[part 1 of 3: packages /MICROSAR/Dem_swc/DataTypes to /MICROSAR/Dem_swc/ComponentTypes]
AUTOSAR XML (schema 4-3-0)
package /MICROSAR/Dem_swc/DataTypes
  26 x impl type:
    Dem_EventIdType: range raw 1..65535, implementation-data-type=uint16
    Dem_RatioIdType: range raw 1..65535, implementation-data-type=uint16
    Dem_DTCStatusMaskType: range raw 0..255, implementation-data-type=uint8
    Dem_OperationCycleIdType: range raw 0..255, implementation-data-type=uint8
    Dem_DTCGroupType: range raw 0..16777215, implementation-data-type=uint32
    Dem_UdsStatusByteType: compu {mask 1: 1=DEM_UDS_STATUS_TF, mask 2: 2=DEM_UDS_STATUS_TFTOC, mask 4: 4=DEM_UDS_STATUS_PDTC, mask 8: 8=DEM_UDS_STATUS_CDTC, mask 16: 16=DEM_UDS_STATUS_TNCSLC, mask 32: 32=DEM_UDS_STATUS_TFSLC, mask 64: 64=DEM_UDS_STATUS_TNCTOC, mask 128: 128=DEM_UDS_STATUS_WIR}, range raw 0..255, implementation-data-type=uint8
    Dem_InitMonitorReasonType: compu {1=DEM_INIT_MONITOR_CLEAR, 2=DEM_INIT_MONITOR_RESTART, 3=DEM_INIT_MONITOR_REENABLED, 4=DEM_INIT_MONITOR_STORAGE_REENABLED}, implementation-data-type=uint8
    Dem_DTCFormatType: compu {0=DEM_DTC_FORMAT_OBD, 1=DEM_DTC_FORMAT_UDS, 2=DEM_DTC_FORMAT_J1939}, implementation-data-type=uint8
    Dem_OperationCycleStateType: compu {0=DEM_CYCLE_STATE_START, 1=DEM_CYCLE_STATE_END}, implementation-data-type=uint8
    Dem_IndicatorStatusType: compu {0=DEM_INDICATOR_OFF, 1=DEM_INDICATOR_CONTINUOUS, 2=DEM_INDICATOR_BLINKING, 3=DEM_INDICATOR_BLINK_CONT, 4=DEM_INDICATOR_SLOW_FLASH, 5=DEM_INDICATOR_FAST_FLASH, 6=DEM_INDICATOR_ON_DEMAND, 7=DEM_INDICATOR_SHORT}, implementation-data-type=uint8
    Dem_DTCKindType: compu {1=DEM_DTC_KIND_ALL_DTCS, 2=DEM_DTC_KIND_EMISSION_REL_DTCS}, implementation-data-type=uint8
    Dem_IumprDenomCondIdType: compu {1=DEM_IUMPR_GENERAL_DENOMINATOR, 2=DEM_IUMPR_DEN_COND_COLDSTART, 3=DEM_IUMPR_DEN_COND_EVAP, 4=DEM_IUMPR_DEN_COND_500MI}, implementation-data-type=uint8
    Dem_IumprDenomCondStatusType: compu {0=DEM_IUMPR_DEN_STATUS_NOT_REACHED, 1=DEM_IUMPR_DEN_STATUS_REACHED, 2=DEM_IUMPR_DEN_STATUS_INHIBITED}, implementation-data-type=uint8
    Dem_DebounceResetStatusType: compu {0=DEM_DEBOUNCE_STATUS_FREEZE, 1=DEM_DEBOUNCE_STATUS_RESET}, implementation-data-type=uint8
    Dem_DebouncingStateType: compu {mask 1: 1=DEM_TEMPORARILY_DEFECTIVE, mask 2: 2=DEM_FINALLY_DEFECTIVE, mask 4: 4=DEM_TEMPORARILY_HEALED, mask 8: 8=DEM_TEST_COMPLETE, mask 16: 16=DEM_DTR_UPDATE}, range raw 0..255, implementation-data-type=uint8
    Dem_MaxDataValueType: category=ARRAY, sw-calibration-access=READ-ONLY
      element Dem_MaxDataValueTypeElement: array-size=4, array-size-semantics=FIXED-SIZE, implementation-data-type=uint8
    Dem_EventStatusType: compu {0=DEM_EVENT_STATUS_PASSED, 1=DEM_EVENT_STATUS_FAILED, 2=DEM_EVENT_STATUS_PREPASSED, 3=DEM_EVENT_STATUS_PREFAILED, 4=DEM_EVENT_STATUS_FDC_THRESHOLD_REACHED, 5=DEM_EVENT_STATUS_PASSED_CONDITIONS_NOT_FULFILLED, 6=DEM_EVENT_STATUS_FAILED_CONDITIONS_NOT_FULFILLED, 7=DEM_EVENT_STATUS_PREPASSED_CONDITIONS_NOT_FULFILLED, 8=DEM_EVENT_STATUS_PREFAILED_CONDITIONS_NOT_FULFILLED}, implementation-data-type=uint8
    Dem_DTCOriginType: compu {1=DEM_DTC_ORIGIN_PRIMARY_MEMORY, 2=DEM_DTC_ORIGIN_MIRROR_MEMORY, 3=DEM_DTC_ORIGIN_PERMANENT_MEMORY, 4=DEM_DTC_ORIGIN_OBD_RELEVANT_MEMORY, 5=DEM_DTC_ORIGIN_SECONDARY_MEMORY, 5=DEM_DTC_ORIGIN_USERDEFINED_MEMORY_10, 5=DEM_DTC_ORIGIN_USERDEFINED_MEMORY_11, 5=DEM_DTC_ORIGIN_USERDEFINED_MEMORY_12, 5=DEM_DTC_ORIGIN_USERDEFINED_MEMORY_13, 5=DEM_DTC_ORIGIN_USERDEFINED_MEMORY_14, 5=DEM_DTC_ORIGIN_USERDEFINED_MEMORY_15, 5=DEM_DTC_ORIGIN_USERDEFINED_MEMORY_16, 5=DEM_DTC_ORIGIN_USERDEFINED_MEMORY_17, 5=DEM_DTC_ORIGIN_USERDEFINED_MEMORY_18, 5=DEM_DTC_ORIGIN_USERDEFINED_MEMORY_19, 5=DEM_DTC_ORIGIN_USERDEFINED_MEMORY_1A, 5=DEM_DTC_ORIGIN_USERDEFINED_MEMORY_1B, 5=DEM_DTC_ORIGIN_USERDEFINED_MEMORY_1C, 5=DEM_DTC_ORIGIN_USERDEFINED_MEMORY_1D, 5=DEM_DTC_ORIGIN_USERDEFINED_MEMORY_1E, 5=DEM_DTC_ORIGIN_USERDEFINED_MEMORY_1F, 5=DEM_DTC_ORIGIN_USERDEFINED_MEMORY_20, 5=DEM_DTC_ORIGIN_USERDEFINED_MEMORY_21, 5=DEM_DTC_ORIGIN_USERDEFINED_MEMORY_22, 5=DEM_DTC_ORIGIN_USERDEFINED_MEMORY_23, 5=DEM_DTC_ORIGIN_USERDEFINED_MEMORY_24, 5=DEM_DTC_ORIGIN_USERDEFINED_MEMORY_25, 5=DEM_DTC_ORIGIN_USERDEFINED_MEMORY_26, 5=DEM_DTC_ORIGIN_USERDEFINED_MEMORY_27, 5=DEM_DTC_ORIGIN_USERDEFINED_MEMORY_28, 5=DEM_DTC_ORIGIN_USERDEFINED_MEMORY_29, 5=DEM_DTC_ORIGIN_USERDEFINED_MEMORY_2A, 5=DEM_DTC_ORIGIN_USERDEFINED_MEMORY_2B, 5=DEM_DTC_ORIGIN_USERDEFINED_MEMORY_2C, 5=DEM_DTC_ORIGIN_USERDEFINED_MEMORY_2D, 5=DEM_DTC_ORIGIN_USERDEFINED_MEMORY_2E, 5=DEM_DTC_ORIGIN_USERDEFINED_MEMORY_2F, 5=DEM_DTC_ORIGIN_USERDEFINED_MEMORY_30, 5=DEM_DTC_ORIGIN_USERDEFINED_MEMORY_31, 5=DEM_DTC_ORIGIN_USERDEFINED_MEMORY_32, 5=DEM_DTC_ORIGIN_USERDEFINED_MEMORY_33, 5=DEM_DTC_ORIGIN_USERDEFINED_MEMORY_34, 5=DEM_DTC_ORIGIN_USERDEFINED_MEMORY_35, 5=DEM_DTC_ORIGIN_USERDEFINED_MEMORY_36, 5=DEM_DTC_ORIGIN_USERDEFINED_MEMORY_37, 5=DEM_DTC_ORIGIN_USERDEFINED_MEMORY_38, 5=DEM_DTC_ORIGIN_USERDEFINED_MEMORY_39, 5=DEM_DTC_ORIGIN_USERDEFINED_MEMORY_3A, 5=DEM_DTC_ORIGIN_USERDEFINED_MEMORY_3B, 5=DEM_DTC_ORIGIN_USERDEFINED_MEMORY_3C, 5=DEM_DTC_ORIGIN_USERDEFINED_MEMORY_3D, 5=DEM_DTC_ORIGIN_USERDEFINED_MEMORY_3E, 5=DEM_DTC_ORIGIN_USERDEFINED_MEMORY_3F, 5=DEM_DTC_ORIGIN_USERDEFINED_MEMORY_40, 5=DEM_DTC_ORIGIN_USERDEFINED_MEMORY_41, 5=DEM_DTC_ORIGIN_USERDEFINED_MEMORY_42, 5=DEM_DTC_ORIGIN_USERDEFINED_MEMORY_43, 5=DEM_DTC_ORIGIN_USERDEFINED_MEMORY_44, 5=DEM_DTC_ORIGIN_USERDEFINED_MEMORY_45, 5=DEM_DTC_ORIGIN_USERDEFINED_MEMORY_46, 5=DEM_DTC_ORIGIN_USERDEFINED_MEMORY_47, 5=DEM_DTC_ORIGIN_USERDEFINED_MEMORY_48, 5=DEM_DTC_ORIGIN_USERDEFINED_MEMORY_49, 5=DEM_DTC_ORIGIN_USERDEFINED_MEMORY_4A, 5=DEM_DTC_ORIGIN_USERDEFINED_MEMORY_4B, 5=DEM_DTC_ORIGIN_USERDEFINED_MEMORY_4C, 5=DEM_DTC_ORIGIN_USERDEFINED_MEMORY_4D, 5=DEM_DTC_ORIGIN_USERDEFINED_MEMORY_4E, 5=DEM_DTC_ORIGIN_USERDEFINED_MEMORY_4F, 5=DEM_DTC_ORIGIN_USERDEFINED_MEMORY_50, 5=DEM_DTC_ORIGIN_USERDEFINED_MEMORY_51, 5=DEM_DTC_ORIGIN_USERDEFINED_MEMORY_52, 5=DEM_DTC_ORIGIN_USERDEFINED_MEMORY_53, 5=DEM_DTC_ORIGIN_USERDEFINED_MEMORY_54, 5=DEM_DTC_ORIGIN_USERDEFINED_MEMORY_55, 5=DEM_DTC_ORIGIN_USERDEFINED_MEMORY_56, 5=DEM_DTC_ORIGIN_USERDEFINED_MEMORY_57, 5=DEM_DTC_ORIGIN_USERDEFINED_MEMORY_58, 5=DEM_DTC_ORIGIN_USERDEFINED_MEMORY_59, 5=DEM_DTC_ORIGIN_USERDEFINED_MEMORY_5A, 5=DEM_DTC_ORIGIN_USERDEFINED_MEMORY_5B, 5=DEM_DTC_ORIGIN_USERDEFINED_MEMORY_5C, 5=DEM_DTC_ORIGIN_USERDEFINED_MEMORY_5D, 5=DEM_DTC_ORIGIN_USERDEFINED_MEMORY_5E, 5=DEM_DTC_ORIGIN_USERDEFINED_MEMORY_5F, 5=DEM_DTC_ORIGIN_USERDEFINED_MEMORY_60, 5=DEM_DTC_ORIGIN_USERDEFINED_MEMORY_61, 5=DEM_DTC_ORIGIN_USERDEFINED_MEMORY_62, 5=DEM_DTC_ORIGIN_USERDEFINED_MEMORY_63, 5=DEM_DTC_ORIGIN_USERDEFINED_MEMORY_64, 5=DEM_DTC_ORIGIN_USERDEFINED_MEMORY_65, 5=DEM_DTC_ORIGIN_USERDEFINED_MEMORY_66, 5=DEM_DTC_ORIGIN_USERDEFINED_MEMORY_67, 5=DEM_DTC_ORIGIN_USERDEFINED_MEMORY_68, 5=DEM_DTC_ORIGIN_USERDEFINED_MEMORY_69, 5=DEM_DTC_ORIGIN_USERDEFINED_MEMORY_6A, 5=DEM_DTC_ORIGIN_USERDEFINED_MEMORY_6B, 5=DEM_DTC_ORIGIN_USERDEFINED_MEMORY_6C, 5=DEM_DTC_ORIGIN_USERDEFINED_MEMORY_6D, 5=DEM_DTC_ORIGIN_USERDEFINED_MEMORY_6E, 5=DEM_DTC_ORIGIN_USERDEFINED_MEMORY_6F, 5=DEM_DTC_ORIGIN_USERDEFINED_MEMORY_70, 5=DEM_DTC_ORIGIN_USERDEFINED_MEMORY_71, 5=DEM_DTC_ORIGIN_USERDEFINED_MEMORY_72, 5=DEM_DTC_ORIGIN_USERDEFINED_MEMORY_73, 5=DEM_DTC_ORIGIN_USERDEFINED_MEMORY_74, 5=DEM_DTC_ORIGIN_USERDEFINED_MEMORY_75, 5=DEM_DTC_ORIGIN_USERDEFINED_MEMORY_76, 5=DEM_DTC_ORIGIN_USERDEFINED_MEMORY_77, 5=DEM_DTC_ORIGIN_USERDEFINED_MEMORY_78, 5=DEM_DTC_ORIGIN_USERDEFINED_MEMORY_79, 5=DEM_DTC_ORIGIN_USERDEFINED_MEMORY_7A, 5=DEM_DTC_ORIGIN_USERDEFINED_MEMORY_7B, 5=DEM_DTC_ORIGIN_USERDEFINED_MEMORY_7C, 5=DEM_DTC_ORIGIN_USERDEFINED_MEMORY_7D, 5=DEM_DTC_ORIGIN_USERDEFINED_MEMORY_7E, 5=DEM_DTC_ORIGIN_USERDEFINED_MEMORY_7F, 5=DEM_DTC_ORIGIN_USERDEFINED_MEMORY_80, 5=DEM_DTC_ORIGIN_USERDEFINED_MEMORY_81, 5=DEM_DTC_ORIGIN_USERDEFINED_MEMORY_82, 5=DEM_DTC_ORIGIN_USERDEFINED_MEMORY_83, 5=DEM_DTC_ORIGIN_USERDEFINED_MEMORY_84, 5=DEM_DTC_ORIGIN_USERDEFINED_MEMORY_85, 5=DEM_DTC_ORIGIN_USERDEFINED_MEMORY_86, 5=DEM_DTC_ORIGIN_USERDEFINED_MEMORY_87, 5=DEM_DTC_ORIGIN_USERDEFINED_MEMORY_88, 5=DEM_DTC_ORIGIN_USERDEFINED_MEMORY_89, 5=DEM_DTC_ORIGIN_USERDEFINED_MEMORY_8A, 5=DEM_DTC_ORIGIN_USERDEFINED_MEMORY_8B, 5=DEM_DTC_ORIGIN_USERDEFINED_MEMORY_8C, 5=DEM_DTC_ORIGIN_USERDEFINED_MEMORY_8D, 5=DEM_DTC_ORIGIN_USERDEFINED_MEMORY_8E, 5=DEM_DTC_ORIGIN_USERDEFINED_MEMORY_8F, 5=DEM_DTC_ORIGIN_USERDEFINED_MEMORY_90, 5=DEM_DTC_ORIGIN_USERDEFINED_MEMORY_91, 5=DEM_DTC_ORIGIN_USERDEFINED_MEMORY_92, 5=DEM_DTC_ORIGIN_USERDEFINED_MEMORY_93, 5=DEM_DTC_ORIGIN_USERDEFINED_MEMORY_94, 5=DEM_DTC_ORIGIN_USERDEFINED_MEMORY_95, 5=DEM_DTC_ORIGIN_USERDEFINED_MEMORY_96, 5=DEM_DTC_ORIGIN_USERDEFINED_MEMORY_97, 5=DEM_DTC_ORIGIN_USERDEFINED_MEMORY_98, 5=DEM_DTC_ORIGIN_USERDEFINED_MEMORY_99, 5=DEM_DTC_ORIGIN_USERDEFINED_MEMORY_9A, 5=DEM_DTC_ORIGIN_USERDEFINED_MEMORY_9B, 5=DEM_DTC_ORIGIN_USERDEFINED_MEMORY_9C, 5=DEM_DTC_ORIGIN_USERDEFINED_MEMORY_9D, 5=DEM_DTC_ORIGIN_USERDEFINED_MEMORY_9E, 5=DEM_DTC_ORIGIN_USERDEFINED_MEMORY_9F, 5=DEM_DTC_ORIGIN_USERDEFINED_MEMORY_A0, 5=DEM_DTC_ORIGIN_USERDEFINED_MEMORY_A1, 5=DEM_DTC_ORIGIN_USERDEFINED_MEMORY_A2, 5=DEM_DTC_ORIGIN_USERDEFINED_MEMORY_A3, 5=DEM_DTC_ORIGIN_USERDEFINED_MEMORY_A4, 5=DEM_DTC_ORIGIN_USERDEFINED_MEMORY_A5, 5=DEM_DTC_ORIGIN_USERDEFINED_MEMORY_A6, 5=DEM_DTC_ORIGIN_USERDEFINED_MEMORY_A7, 5=DEM_DTC_ORIGIN_USERDEFINED_MEMORY_A8, 5=DEM_DTC_ORIGIN_USERDEFINED_MEMORY_A9, 5=DEM_DTC_ORIGIN_USERDEFINED_MEMORY_AA, 5=DEM_DTC_ORIGIN_USERDEFINED_MEMORY_AB, 5=DEM_DTC_ORIGIN_USERDEFINED_MEMORY_AC, 5=DEM_DTC_ORIGIN_USERDEFINED_MEMORY_AD, 5=DEM_DTC_ORIGIN_USERDEFINED_MEMORY_AE, 5=DEM_DTC_ORIGIN_USERDEFINED_MEMORY_AF, 5=DEM_DTC_ORIGIN_USERDEFINED_MEMORY_B0, 5=DEM_DTC_ORIGIN_USERDEFINED_MEMORY_B1, 5=DEM_DTC_ORIGIN_USERDEFINED_MEMORY_B2, 5=DEM_DTC_ORIGIN_USERDEFINED_MEMORY_B3, 5=DEM_DTC_ORIGIN_USERDEFINED_MEMORY_B4, 5=DEM_DTC_ORIGIN_USERDEFINED_MEMORY_B5, 5=DEM_DTC_ORIGIN_USERDEFINED_MEMORY_B6, 5=DEM_DTC_ORIGIN_USERDEFINED_MEMORY_B7, 5=DEM_DTC_ORIGIN_USERDEFINED_MEMORY_B8, 5=DEM_DTC_ORIGIN_USERDEFINED_MEMORY_B9, 5=DEM_DTC_ORIGIN_USERDEFINED_MEMORY_BA, 5=DEM_DTC_ORIGIN_USERDEFINED_MEMORY_BB, 5=DEM_DTC_ORIGIN_USERDEFINED_MEMORY_BC, 5=DEM_DTC_ORIGIN_USERDEFINED_MEMORY_BD, 5=DEM_DTC_ORIGIN_USERDEFINED_MEMORY_BE, 5=DEM_DTC_ORIGIN_USERDEFINED_MEMORY_BF, 5=DEM_DTC_ORIGIN_USERDEFINED_MEMORY_C0, 5=DEM_DTC_ORIGIN_USERDEFINED_MEMORY_C1, 5=DEM_DTC_ORIGIN_USERDEFINED_MEMORY_C2, 5=DEM_DTC_ORIGIN_USERDEFINED_MEMORY_C3, 5=DEM_DTC_ORIGIN_USERDEFINED_MEMORY_C4, 5=DEM_DTC_ORIGIN_USERDEFINED_MEMORY_C5, 5=DEM_DTC_ORIGIN_USERDEFINED_MEMORY_C6, 5=DEM_DTC_ORIGIN_USERDEFINED_MEMORY_C7, 5=DEM_DTC_ORIGIN_USERDEFINED_MEMORY_C8, 5=DEM_DTC_ORIGIN_USERDEFINED_MEMORY_C9, 5=DEM_DTC_ORIGIN_USERDEFINED_MEMORY_CA, 5=DEM_DTC_ORIGIN_USERDEFINED_MEMORY_CB, 5=DEM_DTC_ORIGIN_USERDEFINED_MEMORY_CC, 5=DEM_DTC_ORIGIN_USERDEFINED_MEMORY_CD, 5=DEM_DTC_ORIGIN_USERDEFINED_MEMORY_CE, 5=DEM_DTC_ORIGIN_USERDEFINED_MEMORY_CF, 5=DEM_DTC_ORIGIN_USERDEFINED_MEMORY_D0, 5=DEM_DTC_ORIGIN_USERDEFINED_MEMORY_D1, 5=DEM_DTC_ORIGIN_USERDEFINED_MEMORY_D2, 5=DEM_DTC_ORIGIN_USERDEFINED_MEMORY_D3, 5=DEM_DTC_ORIGIN_USERDEFINED_MEMORY_D4, 5=DEM_DTC_ORIGIN_USERDEFINED_MEMORY_D5, 5=DEM_DTC_ORIGIN_USERDEFINED_MEMORY_D6, 5=DEM_DTC_ORIGIN_USERDEFINED_MEMORY_D7, 5=DEM_DTC_ORIGIN_USERDEFINED_MEMORY_D8, 5=DEM_DTC_ORIGIN_USERDEFINED_MEMORY_D9, 5=DEM_DTC_ORIGIN_USERDEFINED_MEMORY_DA, 5=DEM_DTC_ORIGIN_USERDEFINED_MEMORY_DB, 5=DEM_DTC_ORIGIN_USERDEFINED_MEMORY_DC, 5=DEM_DTC_ORIGIN_USERDEFINED_MEMORY_DD, 5=DEM_DTC_ORIGIN_USERDEFINED_MEMORY_DE, 5=DEM_DTC_ORIGIN_USERDEFINED_MEMORY_DF, 5=DEM_DTC_ORIGIN_USERDEFINED_MEMORY_E0, 5=DEM_DTC_ORIGIN_USERDEFINED_MEMORY_E1, 5=DEM_DTC_ORIGIN_USERDEFINED_MEMORY_E2, 5=DEM_DTC_ORIGIN_USERDEFINED_MEMORY_E3, 5=DEM_DTC_ORIGIN_USERDEFINED_MEMORY_E4, 5=DEM_DTC_ORIGIN_USERDEFINED_MEMORY_E5, 5=DEM_DTC_ORIGIN_USERDEFINED_MEMORY_E6, 5=DEM_DTC_ORIGIN_USERDEFINED_MEMORY_E7, 5=DEM_DTC_ORIGIN_USERDEFINED_MEMORY_E8, 5=DEM_DTC_ORIGIN_USERDEFINED_MEMORY_E9, 5=DEM_DTC_ORIGIN_USERDEFINED_MEMORY_EA, 5=DEM_DTC_ORIGIN_USERDEFINED_MEMORY_EB, 5=DEM_DTC_ORIGIN_USERDEFINED_MEMORY_EC, 5=DEM_DTC_ORIGIN_USERDEFINED_MEMORY_ED, 5=DEM_DTC_ORIGIN_USERDEFINED_MEMORY_EE, 5=DEM_DTC_ORIGIN_USERDEFINED_MEMORY_EF, 5=DEM_DTC_ORIGIN_USERDEFINED_MEMORY_F0, 5=DEM_DTC_ORIGIN_USERDEFINED_MEMORY_F1, 5=DEM_DTC_ORIGIN_USERDEFINED_MEMORY_F2, 5=DEM_DTC_ORIGIN_USERDEFINED_MEMORY_F3, 5=DEM_DTC_ORIGIN_USERDEFINED_MEMORY_F4, 5=DEM_DTC_ORIGIN_USERDEFINED_MEMORY_F5, 5=DEM_DTC_ORIGIN_USERDEFINED_MEMORY_F6, 5=DEM_DTC_ORIGIN_USERDEFINED_MEMORY_F7, 5=DEM_DTC_ORIGIN_USERDEFINED_MEMORY_F8, 5=DEM_DTC_ORIGIN_USERDEFINED_MEMORY_F9, 5=DEM_DTC_ORIGIN_USERDEFINED_MEMORY_FA, 5=DEM_DTC_ORIGIN_USERDEFINED_MEMORY_FB, 5=DEM_DTC_ORIGIN_USERDEFINED_MEMORY_FC, 5=DEM_DTC_ORIGIN_USERDEFINED_MEMORY_FD, 5=DEM_DTC_ORIGIN_USERDEFINED_MEMORY_FE, 5=DEM_DTC_ORIGIN_USERDEFINED_MEMORY_FF}, implementation-data-type=uint16
    Dem_IumprReadinessGroupType: compu {0=DEM_IUMPR_BOOSTPRS, 1=DEM_IUMPR_CAT1, 2=DEM_IUMPR_CAT2, 3=DEM_IUMPR_EGR, 4=DEM_IUMPR_EGSENSOR, 5=DEM_IUMPR_EVAP, 6=DEM_IUMPR_NMHCCAT, 7=DEM_IUMPR_NOXADSORB, 8=DEM_IUMPR_NOXCAT, 9=DEM_IUMPR_OXS1, 10=DEM_IUMPR_OXS2, 11=DEM_IUMPR_PMFILTER, 12=DEM_IUMPR_PRIVATE, 13=DEM_IUMPR_SAIR, 14=DEM_IUMPR_SECOXS1, 15=DEM_IUMPR_SECOXS2, 16=DEM_IUMPR_FLSYS, 255=DEM_IUMPR_ALLGROUPS}, implementation-data-type=uint8
    Dem_DTRControlType: compu {0=DEM_DTR_CTL_NORMAL, 1=DEM_DTR_CTL_NO_MAX, 2=DEM_DTR_CTL_NO_MIN, 3=DEM_DTR_CTL_RESET, 4=DEM_DTR_CTL_INVISIBLE}, implementation-data-type=uint8
    Dem_DTCSeverityType:
      compu {mask 255: 0=DEM_SEVERITY_NO_SEVERITY, mask 31: 2=DEM_SEVERITY_WWHOBD_CLASS_A, mask 31: 4=DEM_SEVERITY_WWHOBD_CLASS_B1, mask 31: 8=DEM_SEVERITY_WWHOBD_CLASS_B2, mask 31: 16=DEM_SEVERITY_WWHOBD_CLASS_C, mask 31: 1=DEM_SEVERITY_WWHOBD_CLASS_NO_CLASS, mask 224: 64=DEM_SEVERITY_CHECK_AT_NEXT_HALT, mask 224: 128=DEM_SEVERITY_CHECK_IMMEDIATELY, mask 224: 32=DEM_SEVERITY_MAINTENANCE_ONLY}
      range raw 0..255
      implementation-data-type=uint8
    Dem_MonitorStatusType: compu {mask 1: 1=DEM_MONITOR_STATUS_TF, mask 2: 2=DEM_MONITOR_STATUS_TNCTOC}, range raw 0..255, implementation-data-type=uint8
    DataArrayType_uint8_1: category=ARRAY, sw-calibration-access=READ-ONLY
      element DataArrayType_uint8_1Element: array-size=1, array-size-semantics=FIXED-SIZE, implementation-data-type=uint8
    DataArrayType_uint8_3: category=ARRAY, sw-calibration-access=READ-ONLY
      element DataArrayType_uint8_3Element: array-size=3, array-size-semantics=FIXED-SIZE, implementation-data-type=uint8
    DataArrayType_uint8_4: category=ARRAY, sw-calibration-access=READ-ONLY
      element DataArrayType_uint8_4Element: array-size=4, array-size-semantics=FIXED-SIZE, implementation-data-type=uint8
    DataArrayType_uint8_2: category=ARRAY, sw-calibration-access=READ-ONLY
      element DataArrayType_uint8_2Element: array-size=2, array-size-semantics=FIXED-SIZE, implementation-data-type=uint8
package /MICROSAR/Dem_swc/Interfaces
  24 x client server interface, all with is-service=true, service-kind=DIAGNOSTIC-EVENT-MANAGER:
    DemServices
      operation GetPostRunRequested: possible-error=DemServices/E_NOT_OK
        arg IsRequested: type=boolean, direction=OUT
      operation GetDTCStatusAvailabilityMask: possible-error=DemServices/E_NOT_OK
        arg ClientId: type=uint8, direction=IN
        arg DTCStatusMask: type=uint8, direction=OUT
      error E_NOT_OK: error-code=1
    EvMemOverflowIndication
      operation GetEventMemoryOverflow: possible-error=EvMemOverflowIndication/E_NOT_OK
        arg OverflowIndication: type=boolean, direction=OUT
      operation GetNumberOfEventMemoryEntries: possible-error=EvMemOverflowIndication/E_NOT_OK
        arg NumberOfEventMemoryEntries: type=uint8, direction=OUT
      error E_NOT_OK: error-code=1
    GeneralDiagnosticInfo
      11 x operation:
        GetEventStatus: possible-error=GeneralDiagnosticInfo/E_NOT_OK
          arg EventId: type=Dem_EventIdType, direction=IN
          arg UDSStatusByte: type=Dem_UdsStatusByteType, direction=OUT
        GetEventFailed: possible-error=GeneralDiagnosticInfo/E_NOT_OK
          arg EventId: type=Dem_EventIdType, direction=IN
          arg EventFailed: type=boolean, direction=OUT
        GetEventTested: possible-error=GeneralDiagnosticInfo/E_NOT_OK
          arg EventId: type=Dem_EventIdType, direction=IN
          arg EventTested: type=boolean, direction=OUT
        GetDTCOfEvent: possible-error=[GeneralDiagnosticInfo/E_NOT_OK, GeneralDiagnosticInfo/DEM_E_NO_DTC_AVAILABLE]
          arg EventId: type=Dem_EventIdType, direction=IN
          arg DTCFormat: type=Dem_DTCFormatType, direction=IN
          arg DTCOfEvent: type=uint32, direction=OUT
        GetFaultDetectionCounter: possible-error=[GeneralDiagnosticInfo/E_NOT_OK, GeneralDiagnosticInfo/DEM_E_NO_FDC_AVAILABLE]
          arg EventId: type=Dem_EventIdType, direction=IN
          arg FaultDetectionCounter: type=sint8, direction=OUT
        GetEventEnableCondition: possible-error=GeneralDiagnosticInfo/E_NOT_OK
          arg EventId: type=Dem_EventIdType, direction=IN
          arg ConditionFullfilled: type=boolean, direction=OUT
        GetDebouncingOfEvent: possible-error=GeneralDiagnosticInfo/E_NOT_OK
          arg EventId: type=Dem_EventIdType, direction=IN
          arg DebouncingState: type=Dem_DebouncingStateType, direction=OUT
        GetEventUdsStatus: possible-error=GeneralDiagnosticInfo/E_NOT_OK
          arg EventId: type=Dem_EventIdType, direction=IN
          arg UDSStatusByte: type=Dem_UdsStatusByteType, direction=OUT
        GetEventFreezeFrameDataEx: possible-error=[GeneralDiagnosticInfo/E_NOT_OK, GeneralDiagnosticInfo/DEM_BUFFER_TOO_SMALL, GeneralDiagnosticInfo/DEM_NO_SUCH_ELEMENT]
          5 x arg:
            EventId: type=Dem_EventIdType, direction=IN
            RecordNumber: type=uint8, direction=IN
            DataId: type=uint16, direction=IN
            DestBuffer: type=Dem_MaxDataValueType, direction=OUT
            BufSize: type=uint16, direction=INOUT
        GetEventExtendedDataRecordEx: possible-error=[GeneralDiagnosticInfo/E_NOT_OK, GeneralDiagnosticInfo/DEM_BUFFER_TOO_SMALL, GeneralDiagnosticInfo/DEM_NO_SUCH_ELEMENT]
          4 x arg:
            EventId: type=Dem_EventIdType, direction=IN
            RecordNumber: type=uint8, direction=IN
            DestBuffer: type=Dem_MaxDataValueType, direction=OUT
            BufSize: type=uint16, direction=INOUT
        GetMonitorStatus: possible-error=GeneralDiagnosticInfo/E_NOT_OK
          arg EventId: type=Dem_EventIdType, direction=IN
          arg MonitorStatus: type=Dem_MonitorStatusType, direction=OUT
      5 x error:
        E_NOT_OK: error-code=1
        DEM_E_NO_DTC_AVAILABLE: error-code=10
        DEM_E_NO_FDC_AVAILABLE: error-code=14
        DEM_BUFFER_TOO_SMALL: error-code=21
        DEM_NO_SUCH_ELEMENT: error-code=48
    DiagnosticInfo
      11 x operation:
        GetEventStatus: possible-error=DiagnosticInfo/E_NOT_OK
          arg UDSStatusByte: type=Dem_UdsStatusByteType, direction=OUT
        GetEventFailed: possible-error=DiagnosticInfo/E_NOT_OK
          arg EventFailed: type=boolean, direction=OUT
        GetEventTested: possible-error=DiagnosticInfo/E_NOT_OK
          arg EventTested: type=boolean, direction=OUT
        GetDTCOfEvent: possible-error=[DiagnosticInfo/E_NOT_OK, DiagnosticInfo/DEM_E_NO_DTC_AVAILABLE]
          arg DTCFormat: type=Dem_DTCFormatType, direction=IN
          arg DTCOfEvent: type=uint32, direction=OUT
        GetFaultDetectionCounter: possible-error=[DiagnosticInfo/E_NOT_OK, DiagnosticInfo/DEM_E_NO_FDC_AVAILABLE]
          arg FaultDetectionCounter: type=sint8, direction=OUT
        GetEventEnableCondition: possible-error=DiagnosticInfo/E_NOT_OK
          arg ConditionFullfilled: type=boolean, direction=OUT
        GetDebouncingOfEvent: possible-error=DiagnosticInfo/E_NOT_OK
          arg DebouncingState: type=Dem_DebouncingStateType, direction=OUT
        GetEventUdsStatus: possible-error=DiagnosticInfo/E_NOT_OK
          arg UDSStatusByte: type=Dem_UdsStatusByteType, direction=OUT
        GetEventFreezeFrameDataEx: possible-error=[DiagnosticInfo/E_NOT_OK, DiagnosticInfo/DEM_BUFFER_TOO_SMALL, DiagnosticInfo/DEM_NO_SUCH_ELEMENT]
          4 x arg:
            RecordNumber: type=uint8, direction=IN
            DataId: type=uint16, direction=IN
            DestBuffer: type=Dem_MaxDataValueType, direction=OUT
            BufSize: type=uint16, direction=INOUT
        GetEventExtendedDataRecordEx: possible-error=[DiagnosticInfo/E_NOT_OK, DiagnosticInfo/DEM_BUFFER_TOO_SMALL, DiagnosticInfo/DEM_NO_SUCH_ELEMENT]
          arg RecordNumber: type=uint8, direction=IN
          arg DestBuffer: type=Dem_MaxDataValueType, direction=OUT
          arg BufSize: type=uint16, direction=INOUT
        GetMonitorStatus: possible-error=DiagnosticInfo/E_NOT_OK
          arg MonitorStatus: type=Dem_MonitorStatusType, direction=OUT
      5 x error:
        E_NOT_OK: error-code=1
        DEM_E_NO_DTC_AVAILABLE: error-code=10
        DEM_E_NO_FDC_AVAILABLE: error-code=14
        DEM_BUFFER_TOO_SMALL: error-code=21
        DEM_NO_SUCH_ELEMENT: error-code=48
    OperationCycle
      operation SetOperationCycleState: possible-error=[OperationCycle/E_OK, OperationCycle/E_NOT_OK]
        arg CycleState: type=Dem_OperationCycleStateType, direction=IN
      operation GetOperationCycleState: possible-error=[OperationCycle/E_OK, OperationCycle/E_NOT_OK]
        arg CycleState: type=Dem_OperationCycleStateType, direction=OUT
      error E_NOT_OK: error-code=1
      error E_OK: error-code=0
    DiagnosticMonitor
      11 x operation:
        SetEventStatus: possible-error=DiagnosticMonitor/E_NOT_OK
          arg EventStatus: type=Dem_EventStatusType, direction=IN
        ResetEventStatus: possible-error=DiagnosticMonitor/E_NOT_OK
        ResetEventDebounceStatus: possible-error=DiagnosticMonitor/E_NOT_OK
          arg DebounceResetStatus: type=Dem_DebounceResetStatusType, direction=IN
        GetEventStatus: possible-error=DiagnosticMonitor/E_NOT_OK
          arg UDSStatusByte: type=Dem_UdsStatusByteType, direction=OUT
        GetEventFailed: possible-error=DiagnosticMonitor/E_NOT_OK
          arg EventFailed: type=boolean, direction=OUT
        GetEventTested: possible-error=DiagnosticMonitor/E_NOT_OK
          arg EventTested: type=boolean, direction=OUT
        GetDTCOfEvent: possible-error=[DiagnosticMonitor/E_NOT_OK, DiagnosticMonitor/DEM_E_NO_DTC_AVAILABLE]
          arg DTCFormat: type=Dem_DTCFormatType, direction=IN
          arg DTCOfEvent: type=uint32, direction=OUT
        GetFaultDetectionCounter: possible-error=[DiagnosticMonitor/E_NOT_OK, DiagnosticMonitor/DEM_E_NO_FDC_AVAILABLE]
          arg FaultDetectionCounter: type=sint8, direction=OUT
        GetEventUdsStatus: possible-error=DiagnosticMonitor/E_NOT_OK
          arg UDSStatusByte: type=Dem_UdsStatusByteType, direction=OUT
        GetEventFreezeFrameDataEx: possible-error=[DiagnosticMonitor/E_NOT_OK, DiagnosticMonitor/DEM_BUFFER_TOO_SMALL, DiagnosticMonitor/DEM_NO_SUCH_ELEMENT]
          4 x arg:
            RecordNumber: type=uint8, direction=IN
            DataId: type=uint16, direction=IN
            DestBuffer: type=Dem_MaxDataValueType, direction=OUT
            BufSize: type=uint16, direction=INOUT
        GetEventExtendedDataRecordEx: possible-error=[DiagnosticMonitor/E_NOT_OK, DiagnosticMonitor/DEM_BUFFER_TOO_SMALL, DiagnosticMonitor/DEM_NO_SUCH_ELEMENT]
          arg RecordNumber: type=uint8, direction=IN
          arg DestBuffer: type=Dem_MaxDataValueType, direction=OUT
          arg BufSize: type=uint16, direction=INOUT
      5 x error:
        E_NOT_OK: error-code=1
        DEM_E_NO_DTC_AVAILABLE: error-code=10
        DEM_E_NO_FDC_AVAILABLE: error-code=14
        DEM_BUFFER_TOO_SMALL: error-code=21
        DEM_NO_SUCH_ELEMENT: error-code=48
    CallbackClearEventAllowed
      operation ClearEventAllowed: possible-error=CallbackClearEventAllowed/E_NOT_OK
        arg Allowed: type=boolean, direction=OUT
      error E_NOT_OK: error-code=1
    EnableCondition
      operation SetEnableCondition: possible-error=EnableCondition/E_NOT_OK
        arg ConditionFulfilled: type=boolean, direction=IN
      error E_NOT_OK: error-code=1
    GeneralCallbackEventDataChanged
      operation EventDataChanged
        arg EventId: type=Dem_EventIdType, direction=IN
    IndicatorStatus
      operation GetIndicatorStatus: possible-error=IndicatorStatus/E_NOT_OK
        arg IndicatorStatus: type=Dem_IndicatorStatusType, direction=OUT
      error E_NOT_OK: error-code=1
    ClearDTC
      operation ClearDTC: possible-error=[ClearDTC/E_NOT_OK, DEM_CLEAR_FAILED, DEM_PENDING, DEM_CLEAR_BUSY, DEM_CLEAR_MEMORY_ERROR, DEM_WRONG_DTC, DEM_WRONG_DTCORIGIN]
      operation SelectDTC: possible-error=[ClearDTC/E_OK, ClearDTC/E_NOT_OK]
        arg DTC: type=uint32, direction=IN
        arg DTCFormat: type=Dem_DTCFormatType, direction=IN
        arg DTCOrigin: type=Dem_DTCOriginType, direction=IN
      8 x error:
        E_OK: error-code=0
        E_NOT_OK: error-code=1
        DEM_CLEAR_FAILED: error-code=7
        DEM_PENDING: error-code=4
        DEM_CLEAR_BUSY: error-code=5
        DEM_CLEAR_MEMORY_ERROR: error-code=6
        DEM_WRONG_DTC: error-code=8
        DEM_WRONG_DTCORIGIN: error-code=9
    CSDataServices_DID_2866_Betriebsspannung
      operation ReadData: possible-error=CSDataServices_DID_2866_Betriebsspannung/E_NOT_OK
        arg Data: type=DataArrayType_uint8_1, direction=OUT
      error E_NOT_OK: error-code=1
    CSDataServices_DID_1750_FUwBn
      operation ReadData: possible-error=CSDataServices_DID_1750_FUwBn/E_NOT_OK
        arg Data: type=DataArrayType_uint8_1, direction=OUT
      error E_NOT_OK: error-code=1
    CSDataServices_DID_2805_Aussentemperatur
      operation ReadData: possible-error=CSDataServices_DID_2805_Aussentemperatur/E_NOT_OK
        arg Data: type=DataArrayType_uint8_1, direction=OUT
      error E_NOT_OK: error-code=1
    CSDataServices_EDR_02_OccurrenceCounter
      operation ReadData: possible-error=CSDataServices_EDR_02_OccurrenceCounter/E_NOT_OK
        arg Data: type=DataArrayType_uint8_1, direction=OUT
      error E_NOT_OK: error-code=1
    CSDataServices_DID_2867_Fahrzeuggeschwindigkeit
      operation ReadData: possible-error=CSDataServices_DID_2867_Fahrzeuggeschwindigkeit/E_NOT_OK
        arg Data: type=DataArrayType_uint8_1, direction=OUT
      error E_NOT_OK: error-code=1
    CSDataServices_DID_1701_Systemzeit
      operation ReadData: possible-error=CSDataServices_DID_1701_Systemzeit/E_NOT_OK
        arg Data: type=DataArrayType_uint8_4, direction=OUT
      error E_NOT_OK: error-code=1
    CSDataServices_EDR_03_HealingCounter
      operation ReadData: possible-error=CSDataServices_EDR_03_HealingCounter/E_NOT_OK
        arg Data: type=DataArrayType_uint8_1, direction=OUT
      error E_NOT_OK: error-code=1
    CSDataServices_DID_1700_KmStand
      operation ReadData: possible-error=CSDataServices_DID_1700_KmStand/E_NOT_OK
        arg Data: type=DataArrayType_uint8_3, direction=OUT
      error E_NOT_OK: error-code=1
    CSDataServices_EDR_01_ConditionByte
      operation ReadData: possible-error=CSDataServices_EDR_01_ConditionByte/E_NOT_OK
        arg Data: type=DataArrayType_uint8_1, direction=OUT
      error E_NOT_OK: error-code=1
    CSDataServices_DID_5003_HwAg
      operation ReadData: possible-error=CSDataServices_DID_5003_HwAg/E_NOT_OK
        arg Data: type=DataArrayType_uint8_2, direction=OUT
      error E_NOT_OK: error-code=1
    CSDataServices_DID_500C_PscmSts
      operation ReadData: possible-error=CSDataServices_DID_500C_PscmSts/E_NOT_OK
        arg Data: type=DataArrayType_uint8_2, direction=OUT
      error E_NOT_OK: error-code=1
    CSDataServices_DID_500E_HwTq
      operation ReadData: possible-error=CSDataServices_DID_500E_HwTq/E_NOT_OK
        arg Data: type=DataArrayType_uint8_2, direction=OUT
      error E_NOT_OK: error-code=1
    CSDataServices_DID_500F_MotTq
      operation ReadData: possible-error=CSDataServices_DID_500F_MotTq/E_NOT_OK
        arg Data: type=DataArrayType_uint8_2, direction=OUT
      error E_NOT_OK: error-code=1
package /MICROSAR/Dem_swc/ComponentTypes
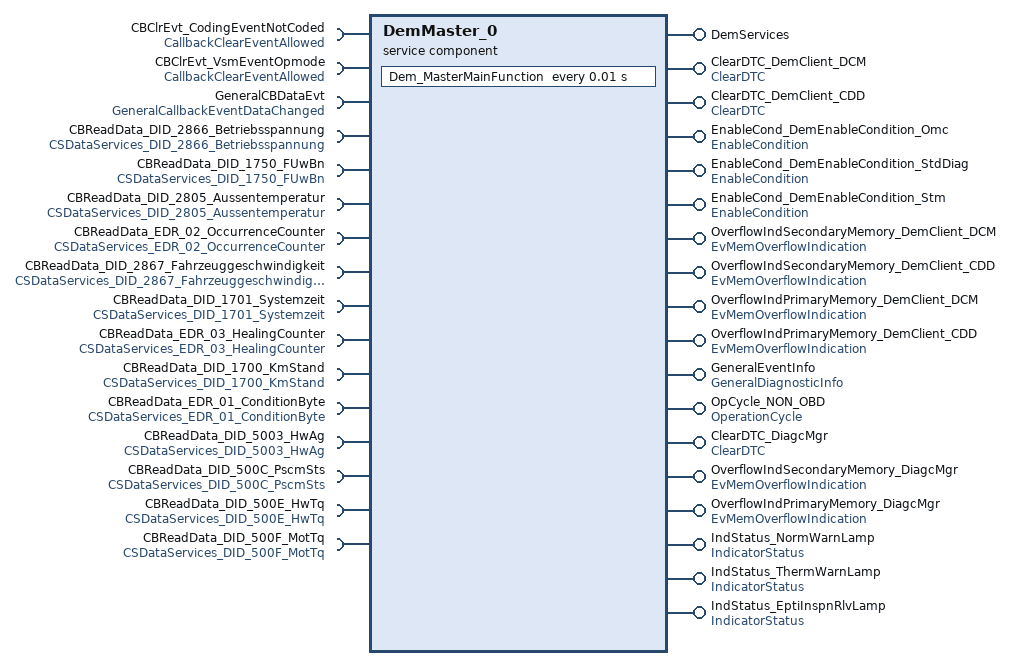
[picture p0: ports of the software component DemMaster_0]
  service sw component type DemMaster_0: category=SERVICE_COMPONENT
    provide port DemServices: provided-interface=DemServices
    require port CBClrEvt_CodingEventNotCoded: required-interface=CallbackClearEventAllowed
    require port CBClrEvt_VsmEventOpmode: required-interface=CallbackClearEventAllowed
    11 x provide port:
      ClearDTC_DemClient_DCM: provided-interface=ClearDTC
      ClearDTC_DemClient_CDD: provided-interface=ClearDTC
      EnableCond_DemEnableCondition_Omc: provided-interface=EnableCondition
      EnableCond_DemEnableCondition_StdDiag: provided-interface=EnableCondition
      EnableCond_DemEnableCondition_Stm: provided-interface=EnableCondition
      OverflowIndSecondaryMemory_DemClient_DCM: provided-interface=EvMemOverflowIndication
      OverflowIndSecondaryMemory_DemClient_CDD: provided-interface=EvMemOverflowIndication
      OverflowIndPrimaryMemory_DemClient_DCM: provided-interface=EvMemOverflowIndication
      OverflowIndPrimaryMemory_DemClient_CDD: provided-interface=EvMemOverflowIndication
      GeneralEventInfo: provided-interface=GeneralDiagnosticInfo
      OpCycle_NON_OBD: provided-interface=OperationCycle
    10 x require port:
      GeneralCBDataEvt: required-interface=GeneralCallbackEventDataChanged
      CBReadData_DID_2866_Betriebsspannung: required-interface=CSDataServices_DID_2866_Betriebsspannung
      CBReadData_DID_1750_FUwBn: required-interface=CSDataServices_DID_1750_FUwBn
      CBReadData_DID_2805_Aussentemperatur: required-interface=CSDataServices_DID_2805_Aussentemperatur
      CBReadData_EDR_02_OccurrenceCounter: required-interface=CSDataServices_EDR_02_OccurrenceCounter
      CBReadData_DID_2867_Fahrzeuggeschwindigkeit: required-interface=CSDataServices_DID_2867_Fahrzeuggeschwindigkeit
      CBReadData_DID_1701_Systemzeit: required-interface=CSDataServices_DID_1701_Systemzeit
      CBReadData_EDR_03_HealingCounter: required-interface=CSDataServices_EDR_03_HealingCounter
      CBReadData_DID_1700_KmStand: required-interface=CSDataServices_DID_1700_KmStand
      CBReadData_EDR_01_ConditionByte: required-interface=CSDataServices_EDR_01_ConditionByte
    6 x provide port:
      ClearDTC_DiagcMgr: provided-interface=ClearDTC
      OverflowIndSecondaryMemory_DiagcMgr: provided-interface=EvMemOverflowIndication
      OverflowIndPrimaryMemory_DiagcMgr: provided-interface=EvMemOverflowIndication
      IndStatus_NormWarnLamp: provided-interface=IndicatorStatus
      IndStatus_ThermWarnLamp: provided-interface=IndicatorStatus
      IndStatus_EptiInspnRlvLamp: provided-interface=IndicatorStatus
    4 x require port:
      CBReadData_DID_5003_HwAg: required-interface=CSDataServices_DID_5003_HwAg
      CBReadData_DID_500C_PscmSts: required-interface=CSDataServices_DID_500C_PscmSts
      CBReadData_DID_500E_HwTq: required-interface=CSDataServices_DID_500E_HwTq
      CBReadData_DID_500F_MotTq: required-interface=CSDataServices_DID_500F_MotTq
    behavior DemMaster_0InternalBehavior: handle-termination-and-restart=NO-SUPPORT, included-data-type-set=data-type=[Dem_EventIdType, Dem_RatioIdType, Dem_EventStatusType, Dem_UdsStatusByteType, Dem_DTCFormatType, Dem_InitMonitorReasonType, Dem_OperationCycleStateType, Dem_DTCStatusMaskType, Dem_IndicatorStatusType, Dem_MaxDataValueType, Dem_DTCKindType, Dem_DTCGroupType, Dem_IumprDenomCondIdType, Dem_IumprDenomCondStatusType, Dem_DebounceResetStatusType, Dem_DebouncingStateType, Dem_IumprReadinessGroupType, Dem_DTRControlType, Dem_DTCSeverityType, Dem_MonitorStatusType]
      timing event Timer_Dem_MasterMainFunction: start-on-event=Dem_MasterMainFunction, period=0.01
      39 x operation invoked event:
        OpEventPostRunRequested_GetPostRunRequested_DemServices: start-on-event=PostRunRequested, operation=DemServices.GetPostRunRequested
        OpEventGetDTCStatusAvailabilityMask_GetDTCStatusAvailabilityMask_DemServices: start-on-event=GetDTCStatusAvailabilityMask, operation=DemServices.GetDTCStatusAvailabilityMask
        OpEventClearDTC_ClearDTC_ClearDTC_DemClient_DCM: start-on-event=ClearDTC, operation=ClearDTC_DemClient_DCM.ClearDTC
        OpEventClearDTC_ClearDTC_ClearDTC_DemClient_CDD: start-on-event=ClearDTC, operation=ClearDTC_DemClient_CDD.ClearDTC
        OpEventSelectDTC_SelectDTC_ClearDTC_DemClient_DCM: start-on-event=SelectDTC, operation=ClearDTC_DemClient_DCM.SelectDTC
        OpEventSelectDTC_SelectDTC_ClearDTC_DemClient_CDD: start-on-event=SelectDTC, operation=ClearDTC_DemClient_CDD.SelectDTC
        OpEventSetEnableCondition_SetEnableCondition_EnableCond_DemEnableCondition_Omc: start-on-event=SetEnableCondition, operation=EnableCond_DemEnableCondition_Omc.SetEnableCondition
        OpEventSetEnableCondition_SetEnableCondition_EnableCond_DemEnableCondition_StdDiag: start-on-event=SetEnableCondition, operation=EnableCond_DemEnableCondition_StdDiag.SetEnableCondition
        OpEventSetEnableCondition_SetEnableCondition_EnableCond_DemEnableCondition_Stm: start-on-event=SetEnableCondition, operation=EnableCond_DemEnableCondition_Stm.SetEnableCondition
        OpEventGetEventMemoryOverflow_GetEventMemoryOverflow_OverflowIndSecondaryMemory_DemClient_DCM: start-on-event=GetEventMemoryOverflow, operation=OverflowIndSecondaryMemory_DemClient_DCM.GetEventMemoryOverflow
        OpEventGetEventMemoryOverflow_GetEventMemoryOverflow_OverflowIndSecondaryMemory_DemClient_CDD: start-on-event=GetEventMemoryOverflow, operation=OverflowIndSecondaryMemory_DemClient_CDD.GetEventMemoryOverflow
        OpEventGetEventMemoryOverflow_GetEventMemoryOverflow_OverflowIndPrimaryMemory_DemClient_DCM: start-on-event=GetEventMemoryOverflow, operation=OverflowIndPrimaryMemory_DemClient_DCM.GetEventMemoryOverflow
        OpEventGetEventMemoryOverflow_GetEventMemoryOverflow_OverflowIndPrimaryMemory_DemClient_CDD: start-on-event=GetEventMemoryOverflow, operation=OverflowIndPrimaryMemory_DemClient_CDD.GetEventMemoryOverflow
        OpEventGetNumberOfEventMemoryEntries_GetNumberOfEventMemoryEntries_OverflowIndSecondaryMemory_DemClient_DCM: start-on-event=GetNumberOfEventMemoryEntries, operation=OverflowIndSecondaryMemory_DemClient_DCM.GetNumberOfEventMemoryEntries
        OpEventGetNumberOfEventMemoryEntries_GetNumberOfEventMemoryEntries_OverflowIndSecondaryMemory_DemClient_CDD: start-on-event=GetNumberOfEventMemoryEntries, operation=OverflowIndSecondaryMemory_DemClient_CDD.GetNumberOfEventMemoryEntries
        OpEventGetNumberOfEventMemoryEntries_GetNumberOfEventMemoryEntries_OverflowIndPrimaryMemory_DemClient_DCM: start-on-event=GetNumberOfEventMemoryEntries, operation=OverflowIndPrimaryMemory_DemClient_DCM.GetNumberOfEventMemoryEntries
        OpEventGetNumberOfEventMemoryEntries_GetNumberOfEventMemoryEntries_OverflowIndPrimaryMemory_DemClient_CDD: start-on-event=GetNumberOfEventMemoryEntries, operation=OverflowIndPrimaryMemory_DemClient_CDD.GetNumberOfEventMemoryEntries
        OpEventGetEventUdsStatus_GetEventUdsStatus_GeneralEventInfo: start-on-event=DemMaster_0InternalBehavior/GetEventUdsStatus, operation=GeneralEventInfo.GetEventUdsStatus
        OpEventGetEventStatus_GetEventStatus_GeneralEventInfo: start-on-event=DemMaster_0InternalBehavior/GetEventStatus, operation=GeneralEventInfo.GetEventStatus
        OpEventGetEventFailed_GetEventFailed_GeneralEventInfo: start-on-event=DemMaster_0InternalBehavior/GetEventFailed, operation=GeneralEventInfo.GetEventFailed
        OpEventGetEventTested_GetEventTested_GeneralEventInfo: start-on-event=DemMaster_0InternalBehavior/GetEventTested, operation=GeneralEventInfo.GetEventTested
        OpEventGetDTCOfEvent_GetDTCOfEvent_GeneralEventInfo: start-on-event=DemMaster_0InternalBehavior/GetDTCOfEvent, operation=GeneralEventInfo.GetDTCOfEvent
        OpEventGetFaultDetectionCounter_GetFaultDetectionCounter_GeneralEventInfo: start-on-event=DemMaster_0InternalBehavior/GetFaultDetectionCounter, operation=GeneralEventInfo.GetFaultDetectionCounter
        OpEventGetEventFreezeFrameDataEx_GetEventFreezeFrameDataEx_GeneralEventInfo: start-on-event=DemMaster_0InternalBehavior/GetEventFreezeFrameDataEx, operation=GeneralEventInfo.GetEventFreezeFrameDataEx
        OpEventGetEventExtendedDataRecordEx_GetEventExtendedDataRecordEx_GeneralEventInfo: start-on-event=DemMaster_0InternalBehavior/GetEventExtendedDataRecordEx, operation=GeneralEventInfo.GetEventExtendedDataRecordEx
        OpEventGetEventEnableCondition_GetEventEnableCondition_GeneralEventInfo: start-on-event=DemMaster_0InternalBehavior/GetEventEnableCondition, operation=GeneralEventInfo.GetEventEnableCondition
        OpEventGetDebouncingOfEvent_GetDebouncingOfEvent_GeneralEventInfo: start-on-event=DemMaster_0InternalBehavior/GetDebouncingOfEvent, operation=GeneralEventInfo.GetDebouncingOfEvent
        OpEventGetMonitorStatus_GetMonitorStatus_GeneralEventInfo: start-on-event=DemMaster_0InternalBehavior/GetMonitorStatus, operation=GeneralEventInfo.GetMonitorStatus
        OpEventGetOperationCycleState_GetOperationCycleState_OpCycle_NON_OBD: start-on-event=GetOperationCycleState, operation=OpCycle_NON_OBD.GetOperationCycleState
        OpEventSetOperationCycleState_SetOperationCycleState_OpCycle_NON_OBD: start-on-event=SetOperationCycleState, operation=OpCycle_NON_OBD.SetOperationCycleState
        OpEventClearDTC_ClearDTC_ClearDTC_DiagcMgr: start-on-event=ClearDTC, operation=ClearDTC_DiagcMgr.ClearDTC
        OpEventSelectDTC_SelectDTC_ClearDTC_DiagcMgr: start-on-event=SelectDTC, operation=ClearDTC_DiagcMgr.SelectDTC
        OpEventGetEventMemoryOverflow_GetEventMemoryOverflow_OverflowIndSecondaryMemory_DiagcMgr: start-on-event=GetEventMemoryOverflow, operation=OverflowIndSecondaryMemory_DiagcMgr.GetEventMemoryOverflow
        OpEventGetEventMemoryOverflow_GetEventMemoryOverflow_OverflowIndPrimaryMemory_DiagcMgr: start-on-event=GetEventMemoryOverflow, operation=OverflowIndPrimaryMemory_DiagcMgr.GetEventMemoryOverflow
        OpEventGetNumberOfEventMemoryEntries_GetNumberOfEventMemoryEntries_OverflowIndSecondaryMemory_DiagcMgr: start-on-event=GetNumberOfEventMemoryEntries, operation=OverflowIndSecondaryMemory_DiagcMgr.GetNumberOfEventMemoryEntries
        OpEventGetNumberOfEventMemoryEntries_GetNumberOfEventMemoryEntries_OverflowIndPrimaryMemory_DiagcMgr: start-on-event=GetNumberOfEventMemoryEntries, operation=OverflowIndPrimaryMemory_DiagcMgr.GetNumberOfEventMemoryEntries
        OpEventGetIndicatorStatus_GetIndicatorStatus_IndStatus_NormWarnLamp: start-on-event=GetIndicatorStatus, operation=IndStatus_NormWarnLamp.GetIndicatorStatus
        OpEventGetIndicatorStatus_GetIndicatorStatus_IndStatus_ThermWarnLamp: start-on-event=GetIndicatorStatus, operation=IndStatus_ThermWarnLamp.GetIndicatorStatus
        OpEventGetIndicatorStatus_GetIndicatorStatus_IndStatus_EptiInspnRlvLamp: start-on-event=GetIndicatorStatus, operation=IndStatus_EptiInspnRlvLamp.GetIndicatorStatus
      port-api-options:
        enable-take-address=true, indirect-api=false, port=DemServices
        enable-take-address=true, indirect-api=false, port=CBClrEvt_CodingEventNotCoded
        enable-take-address=true, indirect-api=false, port=CBClrEvt_VsmEventOpmode
        enable-take-address=true, indirect-api=false, port=DemMaster_0/GeneralEventInfo
        {enable-take-address=true, indirect-api=false, port-defined-argument-value{value=0, value-type=Dem_OperationCycleIdType}, port=OpCycle_NON_OBD}
        enable-take-address=true, indirect-api=false, port=GeneralCBDataEvt
        enable-take-address=true, indirect-api=false, port=CBReadData_DID_2866_Betriebsspannung
        enable-take-address=true, indirect-api=false, port=CBReadData_DID_1750_FUwBn
        enable-take-address=true, indirect-api=false, port=CBReadData_DID_2805_Aussentemperatur
        enable-take-address=true, indirect-api=false, port=CBReadData_EDR_02_OccurrenceCounter
        enable-take-address=true, indirect-api=false, port=CBReadData_DID_2867_Fahrzeuggeschwindigkeit
        enable-take-address=true, indirect-api=false, port=CBReadData_DID_1701_Systemzeit
        enable-take-address=true, indirect-api=false, port=CBReadData_EDR_03_HealingCounter
        enable-take-address=true, indirect-api=false, port=CBReadData_DID_1700_KmStand
        enable-take-address=true, indirect-api=false, port=CBReadData_EDR_01_ConditionByte
        {enable-take-address=true, indirect-api=false, port-defined-argument-value{value=2, value-type=uint8}, port=ClearDTC_DemClient_DCM}
        {enable-take-address=true, indirect-api=false, port-defined-argument-value{value=1, value-type=uint8}, port=ClearDTC_DemClient_CDD}
        {enable-take-address=true, indirect-api=false, port-arg-values=[{value=2, value-type=uint8}, {value=5, value-type=Dem_DTCOriginType}], port=OverflowIndSecondaryMemory_DemClient_DCM}
        {enable-take-address=true, indirect-api=false, port-arg-values=[{value=1, value-type=uint8}, {value=5, value-type=Dem_DTCOriginType}], port=OverflowIndSecondaryMemory_DemClient_CDD}
        {enable-take-address=true, indirect-api=false, port-arg-values=[{value=2, value-type=uint8}, {value=1, value-type=Dem_DTCOriginType}], port=OverflowIndPrimaryMemory_DemClient_DCM}
        {enable-take-address=true, indirect-api=false, port-arg-values=[{value=1, value-type=uint8}, {value=1, value-type=Dem_DTCOriginType}], port=OverflowIndPrimaryMemory_DemClient_CDD}
        {enable-take-address=true, indirect-api=false, port-defined-argument-value{value=0, value-type=uint8}, port=ClearDTC_DiagcMgr}
        {enable-take-address=true, indirect-api=false, port-arg-values=[{value=0, value-type=uint8}, {value=5, value-type=Dem_DTCOriginType}], port=OverflowIndSecondaryMemory_DiagcMgr}
        {enable-take-address=true, indirect-api=false, port-arg-values=[{value=0, value-type=uint8}, {value=1, value-type=Dem_DTCOriginType}], port=OverflowIndPrimaryMemory_DiagcMgr}
        {enable-take-address=true, indirect-api=false, port-defined-argument-value{value=1, value-type=uint8}, port=EnableCond_DemEnableCondition_Omc}
        {enable-take-address=true, indirect-api=false, port-defined-argument-value{value=2, value-type=uint8}, port=EnableCond_DemEnableCondition_StdDiag}
        {enable-take-address=true, indirect-api=false, port-defined-argument-value{value=3, value-type=uint8}, port=EnableCond_DemEnableCondition_Stm}
        {enable-take-address=true, indirect-api=false, port-defined-argument-value{value=0, value-type=uint8}, port=IndStatus_NormWarnLamp}
        {enable-take-address=true, indirect-api=false, port-defined-argument-value{value=1, value-type=uint8}, port=IndStatus_ThermWarnLamp}
        {enable-take-address=true, indirect-api=false, port-defined-argument-value{value=2, value-type=uint8}, port=IndStatus_EptiInspnRlvLamp}
        enable-take-address=true, indirect-api=false, port=CBReadData_DID_5003_HwAg
        enable-take-address=true, indirect-api=false, port=CBReadData_DID_500C_PscmSts
        enable-take-address=true, indirect-api=false, port=CBReadData_DID_500E_HwTq
        enable-take-address=true, indirect-api=false, port=CBReadData_DID_500F_MotTq
      22 x runnable:
        Dem_MasterMainFunction
          16 x sync call, all with timeout=0:
            OpServerCallDem_MasterMainFunction_ClearEventAllowed_CBClrEvt_CodingEventNotCoded: operation=CBClrEvt_CodingEventNotCoded.ClearEventAllowed
            OpServerCallDem_MasterMainFunction_ClearEventAllowed_CBClrEvt_VsmEventOpmode: operation=CBClrEvt_VsmEventOpmode.ClearEventAllowed
            OpServerCallDem_MasterMainFunction_EventDataChanged_GeneralCBDataEvt: operation=GeneralCBDataEvt.EventDataChanged
            OpServerCallDem_MasterMainFunction_ReadData_CBReadData_DID_2866_Betriebsspannung: operation=CBReadData_DID_2866_Betriebsspannung.ReadData
            OpServerCallDem_MasterMainFunction_ReadData_CBReadData_DID_1750_FUwBn: operation=CBReadData_DID_1750_FUwBn.ReadData
            OpServerCallDem_MasterMainFunction_ReadData_CBReadData_DID_2805_Aussentemperatur: operation=CBReadData_DID_2805_Aussentemperatur.ReadData
            OpServerCallDem_MasterMainFunction_ReadData_CBReadData_EDR_02_OccurrenceCounter: operation=CBReadData_EDR_02_OccurrenceCounter.ReadData
            OpServerCallDem_MasterMainFunction_ReadData_CBReadData_DID_2867_Fahrzeuggeschwindigkeit: operation=CBReadData_DID_2867_Fahrzeuggeschwindigkeit.ReadData
            OpServerCallDem_MasterMainFunction_ReadData_CBReadData_DID_1701_Systemzeit: operation=CBReadData_DID_1701_Systemzeit.ReadData
            OpServerCallDem_MasterMainFunction_ReadData_CBReadData_EDR_03_HealingCounter: operation=CBReadData_EDR_03_HealingCounter.ReadData
            OpServerCallDem_MasterMainFunction_ReadData_CBReadData_DID_1700_KmStand: operation=CBReadData_DID_1700_KmStand.ReadData
            OpServerCallDem_MasterMainFunction_ReadData_CBReadData_EDR_01_ConditionByte: operation=CBReadData_EDR_01_ConditionByte.ReadData
            OpServerCallDem_MasterMainFunction_ReadData_CBReadData_DID_5003_HwAg: operation=CBReadData_DID_5003_HwAg.ReadData
            OpServerCallDem_MasterMainFunction_ReadData_CBReadData_DID_500C_PscmSts: operation=CBReadData_DID_500C_PscmSts.ReadData
            OpServerCallDem_MasterMainFunction_ReadData_CBReadData_DID_500E_HwTq: operation=CBReadData_DID_500E_HwTq.ReadData
            OpServerCallDem_MasterMainFunction_ReadData_CBReadData_DID_500F_MotTq: operation=CBReadData_DID_500F_MotTq.ReadData
        PostRunRequested: can-be-invoked-concurrently=true, symbol=Dem_PostRunRequested
        GetDTCStatusAvailabilityMask: can-be-invoked-concurrently=true, symbol=Dem_GetDTCStatusAvailabilityMask
        ClearDTC: can-be-invoked-concurrently=true, symbol=Dem_ClearDTC
        SelectDTC: can-be-invoked-concurrently=true, symbol=Dem_SelectDTC
        SetEnableCondition: can-be-invoked-concurrently=true, symbol=Dem_SetEnableCondition
        GetIndicatorStatus: can-be-invoked-concurrently=true, symbol=Dem_GetIndicatorStatus
        GetEventMemoryOverflow: can-be-invoked-concurrently=true, symbol=Dem_GetEventMemoryOverflow
        GetNumberOfEventMemoryEntries: can-be-invoked-concurrently=true, symbol=Dem_GetNumberOfEventMemoryEntries
        GetEventUdsStatus: can-be-invoked-concurrently=true, symbol=Dem_GetEventUdsStatus
        GetEventStatus: can-be-invoked-concurrently=true, symbol=Dem_GetEventUdsStatus
        GetEventFailed: can-be-invoked-concurrently=true, symbol=Dem_GetEventFailed
        GetEventTested: can-be-invoked-concurrently=true, symbol=Dem_GetEventTested
        GetDTCOfEvent: can-be-invoked-concurrently=true, symbol=Dem_GetDTCOfEvent
        GetFaultDetectionCounter: can-be-invoked-concurrently=true, symbol=Dem_GetFaultDetectionCounter
        GetEventFreezeFrameDataEx: can-be-invoked-concurrently=true, symbol=Dem_GetEventFreezeFrameDataEx
        GetEventExtendedDataRecordEx: can-be-invoked-concurrently=true, symbol=Dem_GetEventExtendedDataRecordEx
        GetEventEnableCondition: can-be-invoked-concurrently=true, symbol=Dem_GetEventEnableCondition
        GetDebouncingOfEvent: can-be-invoked-concurrently=true, symbol=Dem_GetDebouncingOfEvent
        GetMonitorStatus: can-be-invoked-concurrently=true, symbol=Dem_GetMonitorStatus
        GetOperationCycleState: can-be-invoked-concurrently=true, symbol=Dem_GetOperationCycleState
        SetOperationCycleState: can-be-invoked-concurrently=true, symbol=Dem_SetOperationCycleState
  swc implementation DemMaster_0Implementation: programming-language=C, behavior=DemMaster_0InternalBehavior
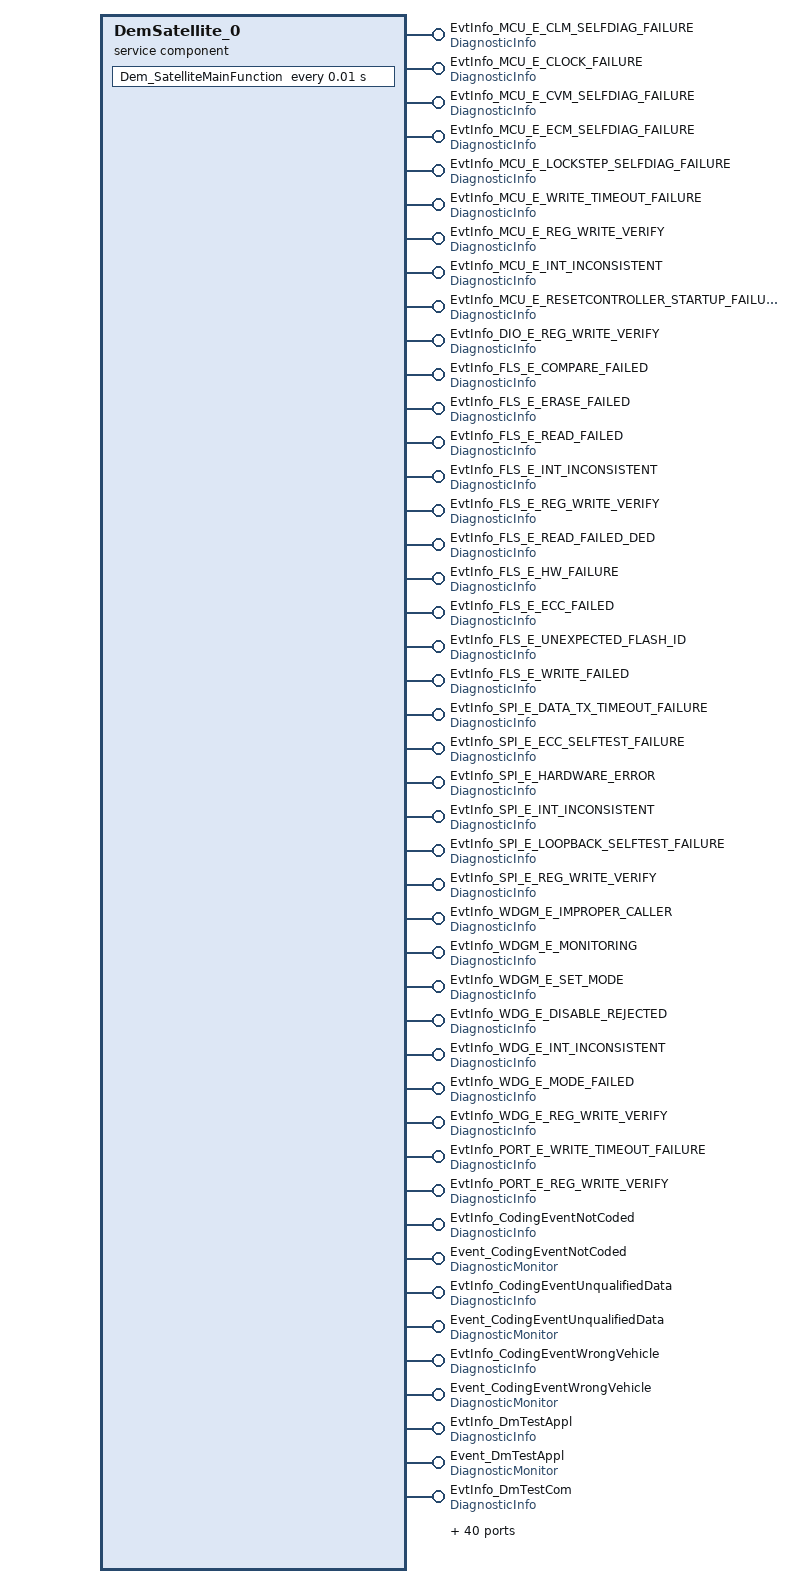
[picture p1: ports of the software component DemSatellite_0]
  service sw component type DemSatellite_0: category=SERVICE_COMPONENT
    84 x provide port:
      EvtInfo_MCU_E_CLM_SELFDIAG_FAILURE: provided-interface=DiagnosticInfo
      EvtInfo_MCU_E_CLOCK_FAILURE: provided-interface=DiagnosticInfo
      EvtInfo_MCU_E_CVM_SELFDIAG_FAILURE: provided-interface=DiagnosticInfo
      EvtInfo_MCU_E_ECM_SELFDIAG_FAILURE: provided-interface=DiagnosticInfo
      EvtInfo_MCU_E_LOCKSTEP_SELFDIAG_FAILURE: provided-interface=DiagnosticInfo
      EvtInfo_MCU_E_WRITE_TIMEOUT_FAILURE: provided-interface=DiagnosticInfo
      EvtInfo_MCU_E_REG_WRITE_VERIFY: provided-interface=DiagnosticInfo
      EvtInfo_MCU_E_INT_INCONSISTENT: provided-interface=DiagnosticInfo
      EvtInfo_MCU_E_RESETCONTROLLER_STARTUP_FAILURE: provided-interface=DiagnosticInfo
      EvtInfo_DIO_E_REG_WRITE_VERIFY: provided-interface=DiagnosticInfo
      EvtInfo_FLS_E_COMPARE_FAILED: provided-interface=DiagnosticInfo
      EvtInfo_FLS_E_ERASE_FAILED: provided-interface=DiagnosticInfo
      EvtInfo_FLS_E_READ_FAILED: provided-interface=DiagnosticInfo
      EvtInfo_FLS_E_INT_INCONSISTENT: provided-interface=DiagnosticInfo
      EvtInfo_FLS_E_REG_WRITE_VERIFY: provided-interface=DiagnosticInfo
      EvtInfo_FLS_E_READ_FAILED_DED: provided-interface=DiagnosticInfo
      EvtInfo_FLS_E_HW_FAILURE: provided-interface=DiagnosticInfo
      EvtInfo_FLS_E_ECC_FAILED: provided-interface=DiagnosticInfo
      EvtInfo_FLS_E_UNEXPECTED_FLASH_ID: provided-interface=DiagnosticInfo
      EvtInfo_FLS_E_WRITE_FAILED: provided-interface=DiagnosticInfo
      EvtInfo_SPI_E_DATA_TX_TIMEOUT_FAILURE: provided-interface=DiagnosticInfo
      EvtInfo_SPI_E_ECC_SELFTEST_FAILURE: provided-interface=DiagnosticInfo
      EvtInfo_SPI_E_HARDWARE_ERROR: provided-interface=DiagnosticInfo
      EvtInfo_SPI_E_INT_INCONSISTENT: provided-interface=DiagnosticInfo
      EvtInfo_SPI_E_LOOPBACK_SELFTEST_FAILURE: provided-interface=DiagnosticInfo
      EvtInfo_SPI_E_REG_WRITE_VERIFY: provided-interface=DiagnosticInfo
      EvtInfo_WDGM_E_IMPROPER_CALLER: provided-interface=DiagnosticInfo
      EvtInfo_WDGM_E_MONITORING: provided-interface=DiagnosticInfo
      EvtInfo_WDGM_E_SET_MODE: provided-interface=DiagnosticInfo
      EvtInfo_WDG_E_DISABLE_REJECTED: provided-interface=DiagnosticInfo
      EvtInfo_WDG_E_INT_INCONSISTENT: provided-interface=DiagnosticInfo
      EvtInfo_WDG_E_MODE_FAILED: provided-interface=DiagnosticInfo
      EvtInfo_WDG_E_REG_WRITE_VERIFY: provided-interface=DiagnosticInfo
      EvtInfo_PORT_E_WRITE_TIMEOUT_FAILURE: provided-interface=DiagnosticInfo
      EvtInfo_PORT_E_REG_WRITE_VERIFY: provided-interface=DiagnosticInfo
      EvtInfo_CodingEventNotCoded: provided-interface=DiagnosticInfo
      Event_CodingEventNotCoded: provided-interface=DiagnosticMonitor
      EvtInfo_CodingEventUnqualifiedData: provided-interface=DiagnosticInfo
      Event_CodingEventUnqualifiedData: provided-interface=DiagnosticMonitor
      EvtInfo_CodingEventWrongVehicle: provided-interface=DiagnosticInfo
      Event_CodingEventWrongVehicle: provided-interface=DiagnosticMonitor
      EvtInfo_DmTestAppl: provided-interface=DiagnosticInfo
      Event_DmTestAppl: provided-interface=DiagnosticMonitor
      EvtInfo_DmTestCom: provided-interface=DiagnosticInfo
      Event_DmTestCom: provided-interface=DiagnosticMonitor
      EvtInfo_FrsmEClusterSyncLoss: provided-interface=DiagnosticInfo
      Event_FrsmEClusterSyncLoss: provided-interface=DiagnosticMonitor
      EvtInfo_FrtrcvEFrBuserrorTrcv0: provided-interface=DiagnosticInfo
      Event_FrtrcvEFrBuserrorTrcv0: provided-interface=DiagnosticMonitor
      EvtInfo_GlobalOvervoltageExt: provided-interface=DiagnosticInfo
      Event_GlobalOvervoltageExt: provided-interface=DiagnosticMonitor
      EvtInfo_GlobalOvervoltageInt: provided-interface=DiagnosticInfo
      Event_GlobalOvervoltageInt: provided-interface=DiagnosticMonitor
      EvtInfo_GlobalUndervoltageExt: provided-interface=DiagnosticInfo
      Event_GlobalUndervoltageExt: provided-interface=DiagnosticMonitor
      EvtInfo_GlobalUndervoltageInt: provided-interface=DiagnosticInfo
      Event_GlobalUndervoltageInt: provided-interface=DiagnosticMonitor
      EvtInfo_LocalOvervoltage: provided-interface=DiagnosticInfo
      Event_LocalOvervoltage: provided-interface=DiagnosticMonitor
      EvtInfo_LocalUndervoltage: provided-interface=DiagnosticInfo
      Event_LocalUndervoltage: provided-interface=DiagnosticMonitor
      EvtInfo_VsmEventOpmode: provided-interface=DiagnosticInfo
      Event_VsmEventOpmode: provided-interface=DiagnosticMonitor
      GeneralEventInfo: provided-interface=GeneralDiagnosticInfo
      EvtInfo_PriEve4822E4_SecEve21F100: provided-interface=DiagnosticInfo
      Event_PriEve4822E4_SecEve21F100: provided-interface=DiagnosticMonitor
      EvtInfo_PriEve4822E4_SecEve31F100: provided-interface=DiagnosticInfo
      Event_PriEve4822E4_SecEve31F100: provided-interface=DiagnosticMonitor
      EvtInfo_PriEve4822F5_SecEve21F300: provided-interface=DiagnosticInfo
      Event_PriEve4822F5_SecEve21F300: provided-interface=DiagnosticMonitor
      EvtInfo_PriEve4822F5_SecEve31F300: provided-interface=DiagnosticInfo
      Event_PriEve4822F5_SecEve31F300: provided-interface=DiagnosticMonitor
      EvtInfo_SecondaryEve_20F300: provided-interface=DiagnosticInfo
      Event_SecondaryEve_20F300: provided-interface=DiagnosticMonitor
      EvtInfo_SecondaryEve_21F100: provided-interface=DiagnosticInfo
      Event_SecondaryEve_21F100: provided-interface=DiagnosticMonitor
      EvtInfo_SecondaryEve_21F300: provided-interface=DiagnosticInfo
      Event_SecondaryEve_21F300: provided-interface=DiagnosticMonitor
      EvtInfo_SecondaryEve_30F300: provided-interface=DiagnosticInfo
      Event_SecondaryEve_30F300: provided-interface=DiagnosticMonitor
      EvtInfo_SecondaryEve_31F100: provided-interface=DiagnosticInfo
      Event_SecondaryEve_31F100: provided-interface=DiagnosticMonitor
      EvtInfo_SecondaryEve_31F300: provided-interface=DiagnosticInfo
      Event_SecondaryEve_31F300: provided-interface=DiagnosticMonitor
    behavior DemSatellite_0InternalBehavior: handle-termination-and-restart=NO-SUPPORT, included-data-type-set=data-type=[Dem_EventIdType, Dem_RatioIdType, Dem_EventStatusType, Dem_UdsStatusByteType, Dem_DTCFormatType, Dem_InitMonitorReasonType, Dem_OperationCycleStateType, Dem_DTCStatusMaskType, Dem_IndicatorStatusType, Dem_MaxDataValueType, Dem_DTCKindType, Dem_DTCGroupType, Dem_IumprDenomCondIdType, Dem_IumprDenomCondStatusType, Dem_DebounceResetStatusType, Dem_DebouncingStateType, Dem_IumprReadinessGroupType, Dem_DTRControlType, Dem_DTCSeverityType, Dem_MonitorStatusType]
      timing event Timer_Dem_SatelliteMainFunction: start-on-event=Dem_SatelliteMainFunction, period=0.01
